# PIC32MX274F256D device description
Architecture: MIPS; Family: PIC32MX; Series: PIC32MX
Registers are 32-bit, read-write, no defined reset value unless marked. A register's access mark holds for its fields unless they carry their own. Offsets are from the block's base; [hi:lo] are bit positions; {n}, {i} and the like mark numbered series; 'fields as' and 'values as' point back to an identical list.

## RCON — Reset Controller
Instances: RCON 0x1f80f000 in periph1
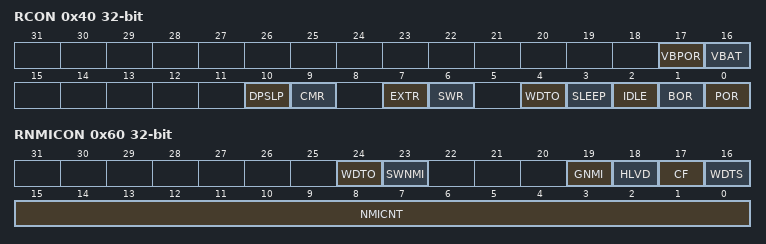
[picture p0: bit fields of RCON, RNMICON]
0x40 RCON — Peripheral Bus Clock Divisor Control Register
  [17] VBPOR — VBPOR Mode Flag bit
    1=POR (A VBAT domain POR has occurred); 0=NO_POR (A VBAT domain POR has not occurred)
  [16] VBAT — VBAT Mode Flag bit
  [10] DPSLP — Deep Sleep Mode Flag bit
    1=DSLP (Deep Sleep mode has occurred); 0=NO_DSLP (Deep Sleep mode has not occurred)
  [9] CMR — Configuration Mismatch Reset Flag bit
    1=MISMATCH (A Configuration Mismatch Reset has occurred); 0=NO_MISMATCH (A Configuration Mismatch Reset has not occurred)
  [7] EXTR — External Reset (MCLR) Pin Flag bit
    1=RESET (Master Clear (pin) Reset has occurred); 0=NO_RESET (Master Clear (pin) Reset has not occurred)
  [6] SWR — Software Reset Flag bit
    1=SW_RESET (Software Reset was executed); 0=NO_SW_RESET (Software Reset was not executed)
  [4] WDTO — Watchdog Timer Time-out Flag bit
    1=WDTO (WDT Time-out has occurred); 0=NO_WDTO (WDT Time-out has not occurred)
  [3] SLEEP — Wake From Sleep Flag bit
    1=SLEEP (Device was in Sleep mode); 0=NO_SLEEP (Device was not in Sleep mode)
  [2] IDLE — Wake From Idle Flag bit
    1=IDLE (Device was in Idle mode); 0=NO_IDLE (Device was not in Idle mode)
  [1] BOR — Brown-out Reset Flag bit
    1=BOR (Brown-out Reset has occurred); 0=NO_BOR (Brown-out Reset has not occurred)
  [0] POR — Power-on Reset Flag bit
    1=POR (Power-on Reset has occurred); 0=NO_POR (Power-on Reset has not occurred)
0x60 RNMICON — Non-maskable Interrupt (NMI) Control Register
  [24] WDTO — Watchdog Timer Time-Out Flag bit
    values as RCON.WDTO
  [23] SWNMI — Software NMI Trigger
  [19] GNMI — General NMI bit
  [18] HLVD — High/Low-Voltage Detect bit
  [17] CF — Clock Fail Detect bit
  [16] WDTS — Watchdog Timer Time-out in Sleep Mode Flag bit
  [15:0] NMICNT — NMI Reset Counter Value bits
0x70 PWRCON — Power Control Register
  [0] VREGS — Voltage Regulator Stand-by Enable bit
Value list RNMICON__WDTO: 1=WDTO (WDT time-out has occurred and caused a NMI); 0=NO_WDTO (WDT time-out has not occurred)
Value list RNMICON__SWNMI: 1=ENABLE (An NMI will be generated); 0=DISABLE (An NMI will not be generated)
Value list RNMICON__GNMI: 1=GNMI (A general NMI event has been detected or a user-initiated NMI event has occurred); 0=NO_GNMI (A general NMI event has not been detected)
Value list RNMICON__HLVD: 1=LOW_VOLTAGE (HLVD has detected a low-voltage condition and caused an NMI); 0=NO_LOW_VOLTAGE (HLVD has not detected a low-voltage condition)
Value list RNMICON__CF: 1=CLK_FAILURE (FSCM has detected clock failure and caused an NMI); 0=NO_CLK_FAILURE (FSCM has not detected clock failure)
Value list RNMICON__WDTS: 1=WDTO (WDT time-out has occurred during Sleep mode and caused a wake-up from sleep); 0=NO_WDTO (WDT time-out has not occurred during Sleep mode)
Value list RNMICON__NMICNT: 0xFFFF=SYSCLK_65535 (65535 SYSCLK cycles before a device Reset occurs); 0=NO_DELAY (No delay between NMI assertion and device Reset event)
Value list PWRCON__VREGS: 1=ACTIVE (Voltage regulator will remain active during Sleep); 0=STDBY (Voltage regulator will go to Stand-by mode during Sleep)

## CTMU
Instances: CTMU 0x1f80a200 in periph0
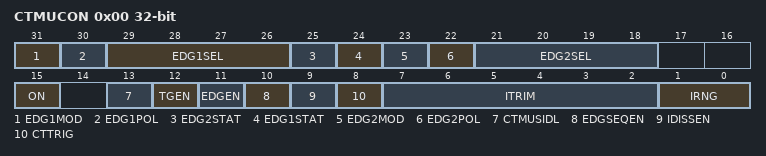
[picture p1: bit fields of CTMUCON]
0x00 CTMUCON — CTMU Control Register
  [31] EDG1MOD — Edge1 Edge Sampling Select bit
    1=Input is edge-sensitive; 0=Input is level-sensitive
  [30] EDG1POL — Edge 1 Polarity Select bit
    1=Edge1 programmed for a positive edge response; 0=Edge1 programmed for a negative edge response
  [29:26] EDG1SEL — Edge 1 Source Select bits
    15=C3OUT pin is selected; 14=C2OUT pin is selected; 13=C1OUT pin is selected; 12=IC3 Capture Event is selected; 11=IC2 Capture Event is selected; 10=IC1 Capture Event is selected; {v}=CTED{v-1} pin is selected (v=4..9); 3=CTED1 pin is selected; 2=CTED2 pin is selected; 1=OC1 Compare Event is selected; 0=Timer1 Event is selected
  [25] EDG2STAT — Edge2 Status bit
    1=Edge2 has occurred; 0=Edge2 has not occurred
  [24] EDG1STAT — Edge1 Status bit
    1=Edge1 has occurred; 0=Edge1 has not occurred
  [23] EDG2MOD — Edge2 Edge Sampling Select bit
    1=Input is edge-sensitive; 0=Input is level-sensitive
  [22] EDG2POL — Edge 2 Polarity Select bit
    1=Edge2 programmed for a positive edge response; 0=Edge2 programmed for a negative edge response
  [21:18] EDG2SEL — Edge 2 Source Select bits
    15=C3OUT pin is selected; 14=C2OUT pin is selected; 13=C1OUT pin is selected; 12=PBCLK clock is selected; 11=IC3 Capture Event is selected; 10=IC2 Capture Event is selected; 9=IC1 Capture Event is selected; {v}=CTED{v+5} pin is selected (v=4..8); 3=CTED1 pin is selected; 2=CTED2 pin is selected; 1=OC1 Compare Event is selected; 0=Timer1 Event is selected
  [15] ON — ON Enable bit
    1=Module is enabled; 0=Module is disabled
  [13] CTMUSIDL — Stop-in-Idle Mode bit
    1=Discontinue module operation when device enters Idle mode; 0=Continue module operation in Idle mode
  [12] TGEN — Time Generation Enable bit
    1=Enables edge delay generation; 0=Disables edge delay generation
  [11] EDGEN — Edge Enable bit
    1=Edges are not blocked; 0=Edges are blocked
  [10] EDGSEQEN — Edge Sequence Enable bit
    1=Edge1 must occur before Edge2 can occur; 0=No edge sequence is needed
  [9] IDISSEN — Analog Current Source Control bit
    1=Analog current source output is grounded; 0=Analog current source output is not grounded
  [8] CTTRIG — Trigger Control bit
    1=Trigger output is enabled; 0=Trigger output is disabled
  [7:2] ITRIM — Current Source Trim bits
    31=Maximum positive change from nominal current; 1=Minimum positive change from nominal current; 0=Nominal current output specified by IRNG; 63=Minimum negative change from nominal current; 33=Maximum negative change from nominal current
  [1:0] IRNG — Current Range Select bits
    3=100 times base current; 2=10 times base current; 1=Base current level; 0=1000 times base current(4)

## Notices in the file
Copyright (c) 2019 Microchip Technology Inc.
SPDX-License-Identifier: Apache-2.0
Licensed under the Apache License, Version 2.0 (the "License");
you may not use this file except in compliance with the License.
You may obtain a copy of the License at
http://www.apache.org/licenses/LICENSE-2.0
Unless required by applicable law or agreed to in writing, software
distributed under the License is distributed on an "AS IS" BASIS,
WITHOUT WARRANTIES OR CONDITIONS OF ANY KIND, either express or implied.
See the License for the specific language governing permissions and
limitations under the License.
